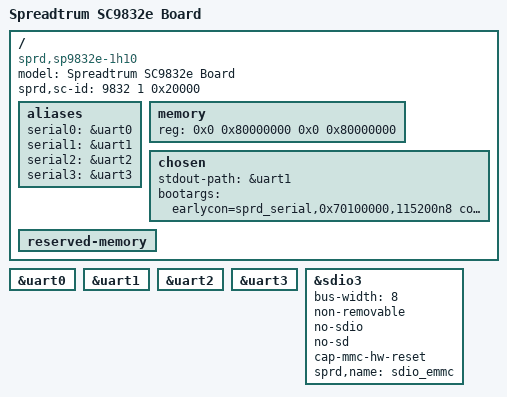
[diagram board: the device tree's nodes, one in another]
/*
 * Spreadtrum sharkle sp9832e board
 *
 * Copyright (C) 2017, Spreadtrum Communications Inc.
 *
 * SPDX-License-Identifier: (GPL-2.0+ OR MIT)
 */
/dts-v1/;

#include "sp9832e-mach.dtsi"

/ {
	model = "Spreadtrum SC9832e Board";

	compatible = "sprd,sp9832e-1h10", "sprd,sc9832e";

	sprd,sc-id = <9832 1 0x20000>;

	aliases {
		serial0 = &uart0; /* for Bluetooth */
		serial1 = &uart1; /* UART console */
		serial2 = &uart2; /* Reserved */
		serial3 = &uart3; /* for GPS */
	};

	memory {
		device_type = "memory";
		reg = <0x0 0x80000000 0x0 0x80000000>;
	};

	chosen {
/*		stdout-path = "serial1:115200n8";*/
		stdout-path = &uart1;
		bootargs = "earlycon=sprd_serial,0x70100000,115200n8 console=ttyS1,115200n8 loglevel=11 init=/init root=/dev/mmcblk0p30 rootfstype=ext4 ro rootwait androidboot.selinux=permissive androidboot.dtbo_idx=0 printk.devkmsg=on";
	};

	reserved-memory {
		#address-cells = <2>;
		#size-cells = <2>;
		ranges;
	};
};

&uart0 {
	status = "okay";
};

&uart1 {
	status = "okay";
};

&uart2 {
	status = "okay";
};

&uart3 {
	status = "okay";
};

&sdio3 {
	bus-width = <8>;
	non-removable;
	no-sdio;
	no-sd;
	cap-mmc-hw-reset;
	sprd,name = "sdio_emmc";
	status = "okay";
};
